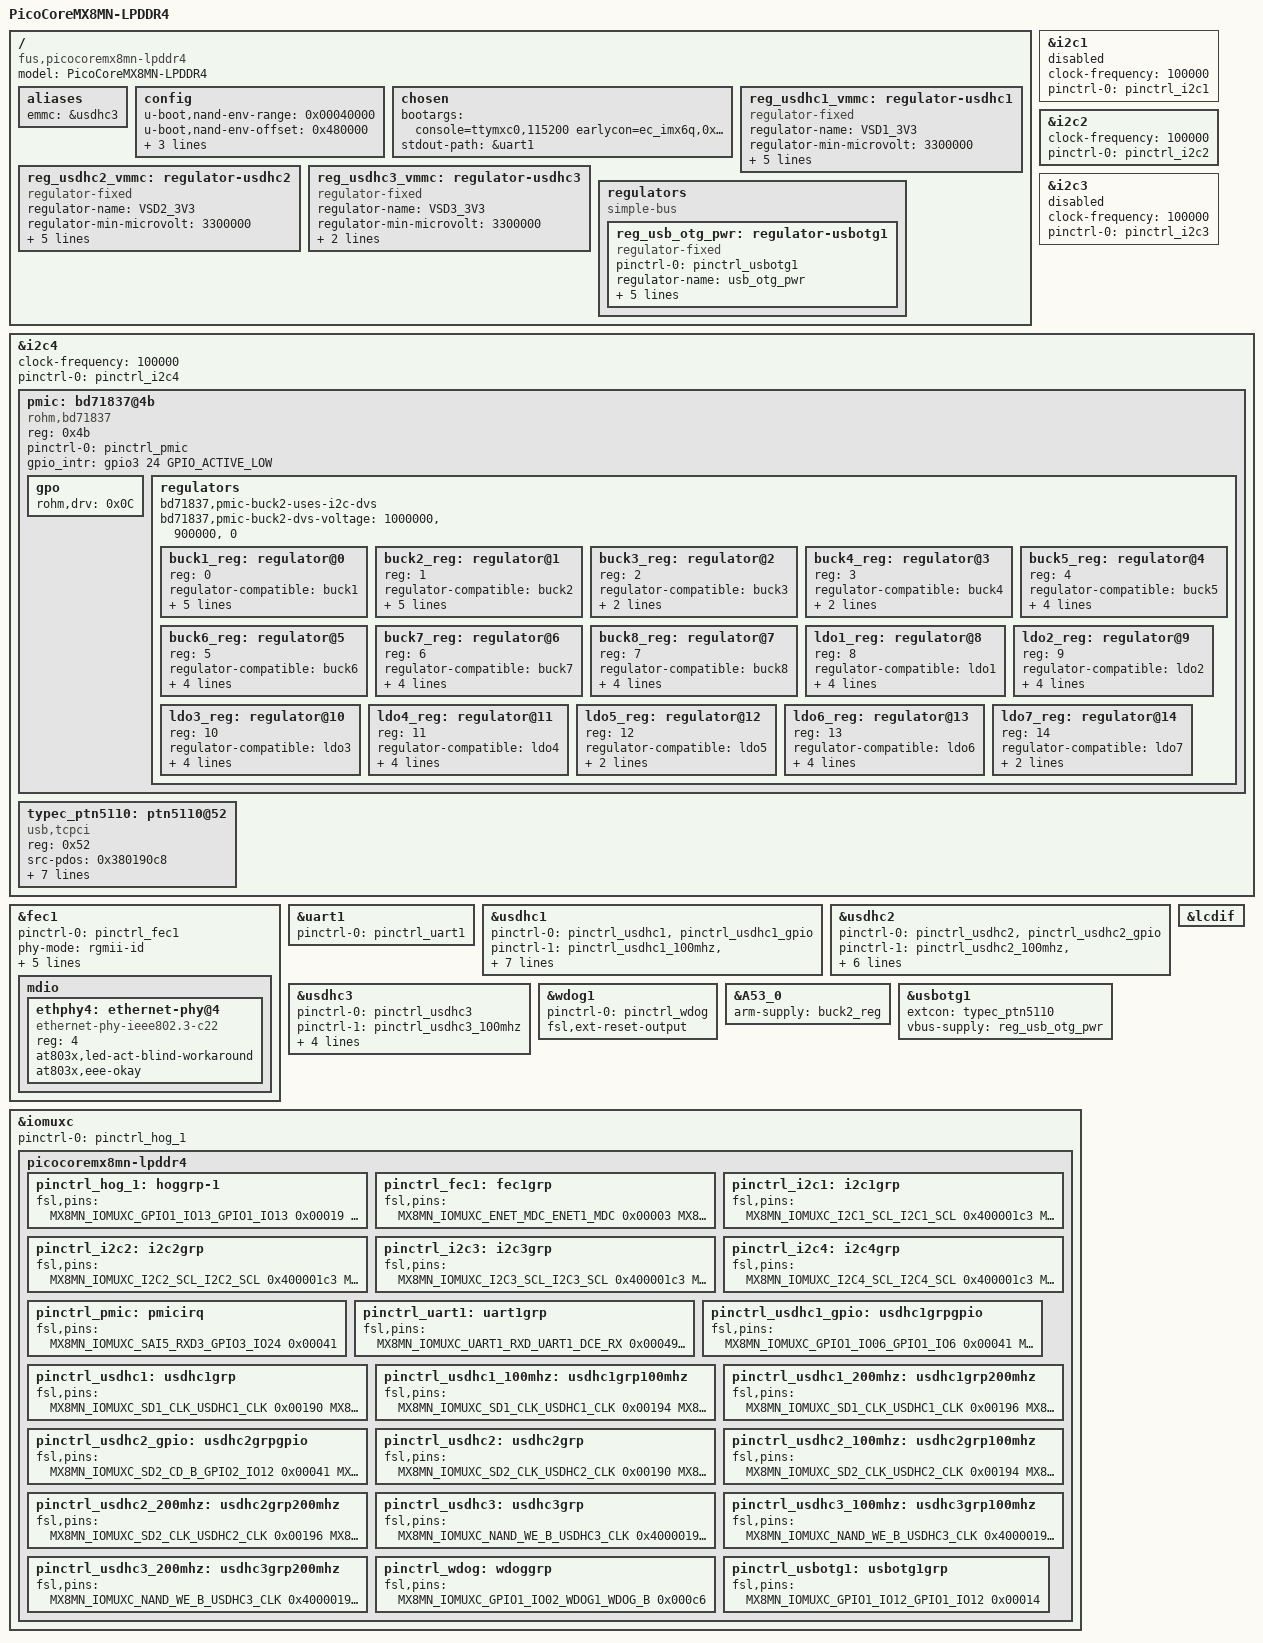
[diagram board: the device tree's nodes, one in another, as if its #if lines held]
/*
* Copyright 2019-2020 F&S Elektronik Systeme GmbH
*
* This program is free software; you can redistribute it and/or
* modify it under the terms of the GNU General Public License
* as published by the Free Software Foundation; either version 2
* of the License, or (at your option) any later version.
*
* This program is distributed in the hope that it will be useful,
* but WITHOUT ANY WARRANTY; without even the implied warranty of
* MERCHANTABILITY or FITNESS FOR A PARTICULAR PURPOSE.  See the
* GNU General Public License for more details.
*
* Remark:
* CONFIG names use "PICOCOREMX8MM" because this is the marking on the PCB.
* This will make it easier to merge the two device trees picocoremx8mm-lpddr4
* and picocoremx8mn-lpddr4 in the future.
*/

/dts-v1/;

/* Set board revision as 3-digit number, e.g. 110 for board rev. 1.10 */
#define CONFIG_PICOCOREMX8MM_BOARD_REVISION	130

 /* Network */
#define CONFIG_PICOCOREMX8MM_ETH

/* USB */
#define CONFIG_PICOCOREMX8MM_USB_OTG1

#define CONFIG_PICOCOREMX8MM_USB_OTG1_TYPEC

/* I2C */
#define CONFIG_PICOCOREMX8MM_I2C_A
#define CONFIG_PICOCOREMX8MM_I2C_B
#define CONFIG_PICOCOREMX8MM_I2C_C
#define CONFIG_PICOCOREMX8MM_I2C_D

/* UART_A - UART1 */
#define CONFIG_PICOCOREMX8MM_UART_A
#define CONFIG_PICOCOREMX8MM_UART_A_RTSCTS


/*
 * SD_A - External SD port with Card Detect (CD) and Write Protect (WP)
 * On PicoCoreMX8MN SKIT: external port is Micro-SD card slot with CD but without WP
 */
#define CONFIG_PICOCOREMX8MM_SD_A
#define CONFIG_PICOCOREMX8MM_SD_A_CD
//#define CONFIG_PICOCOREMX8MM_SD_A_WP

/*
 * SD_B - External SD port with Card Detect (CD) and Write Protect (WP)
 * Not connected on PicoCoreMX8MN SKIT
 */
//#define CONFIG_PICOCOREMX8MM_SD_B
//#define CONFIG_PICOCOREMX8MM_SD_B_CD
//#define CONFIG_PICOCOREMX8MM_SD_B_WP

/* TODO: Power polarity can't be set by DT
*  Default its low for both ports. Use regulator
*  to set pin value to correct state.
*/
/* USB0:
*  Enable regulator to activate
*  power pin for otg host devices.
*/
#define CONFIG_USB_OTG_PWR

#include "imx8mn.dtsi"

/ {
	model = "PicoCoreMX8MN-LPDDR4";
	compatible = "fus,picocoremx8mn-lpddr4", "fsl,imx8mn";

	aliases {
		emmc = &usdhc3;
	};

	config {
		/* Environment in NAND must match UBootEnv MTD partition */
		u-boot,nand-env-range = <0x00040000>;
		u-boot,nand-env-offset = <0x480000>;
		u-boot,nand-env-offset-redundant = <0x4c0000>;

		/* Environment in MMC is in a Boot partition by default */
		u-boot,mmc-env-offset = <0x138000>;
		u-boot,mmc-env-offset-redundant = <0x13c000>;
	};

	chosen {
		bootargs = "console=ttymxc0,115200 earlycon=ec_imx6q,0x30860000,115200";
		stdout-path = &uart1;
	};

#ifdef CONFIG_PICOCOREMX8MM_SD_A
	reg_usdhc1_vmmc: regulator-usdhc1 {
		compatible = "regulator-fixed";
		regulator-name = "VSD1_3V3";
		regulator-min-microvolt = <3300000>;
		regulator-max-microvolt = <3300000>;
		gpio = <&gpio2 10 GPIO_ACTIVE_HIGH>;
		enable-active-high;
		startup-delay-us = <100>;
		off-on-delay-us = <12000>;
	};
#endif

#ifdef CONFIG_PICOCOREMX8MM_SD_B
	reg_usdhc2_vmmc: regulator-usdhc2 {
		compatible = "regulator-fixed";
		regulator-name = "VSD2_3V3";
		regulator-min-microvolt = <3300000>;
		regulator-max-microvolt = <3300000>;
		gpio = <&gpio2 19 GPIO_ACTIVE_HIGH>;
		enable-active-high;
		startup-delay-us = <100>;
		off-on-delay-us = <12000>;
	};
#endif

	reg_usdhc3_vmmc: regulator-usdhc3 {
		compatible = "regulator-fixed";
		regulator-name = "VSD3_3V3";
		regulator-min-microvolt = <3300000>;
		regulator-max-microvolt = <3300000>;
		regulator-always-on;
#if 0
		gpio = <&gpio3 16 GPIO_ACTIVE_HIGH>;
		enable-active-high;
		startup-delay-us = <100>;
		off-on-delay-us = <12000>;
#endif
	};

	regulators {
		compatible = "simple-bus";

#ifdef CONFIG_USB_OTG_PWR
		reg_usb_otg_pwr: regulator-usbotg1 {
			pinctrl-names = "default";
			pinctrl-0 = <&pinctrl_usbotg1>;
			compatible = "regulator-fixed";
			regulator-name = "usb_otg_pwr";
			regulator-min-microvolt = <5000000>;
			regulator-max-microvolt = <5000000>;
			gpio = <&gpio1 12 GPIO_ACTIVE_LOW>;
			startup-delay-us = <100>;
			off-on-delay-us = <12000>;
		};
#endif
	};
};

#ifdef CONFIG_PICOCOREMX8MM_I2C_A
&i2c1 {
	clock-frequency = <100000>;
	pinctrl-names = "default";
	pinctrl-0 = <&pinctrl_i2c1>;
	status = "disabled";
};
#endif

#ifdef CONFIG_PICOCOREMX8MM_I2C_B
&i2c2 {
	clock-frequency = <100000>;
	pinctrl-names = "default";
	pinctrl-0 = <&pinctrl_i2c2>;
	status = "okay";
};
#endif

#ifdef CONFIG_PICOCOREMX8MM_I2C_C
&i2c3 {
	clock-frequency = <100000>;
	pinctrl-names = "default";
	pinctrl-0 = <&pinctrl_i2c3>;
	status = "disabled";
};
#endif

#ifdef CONFIG_PICOCOREMX8MM_I2C_D
&i2c4 {
	clock-frequency = <100000>;
	pinctrl-names = "default";
	pinctrl-0 = <&pinctrl_i2c4>;
	status = "okay";

	pmic: bd71837@4b {
		reg = <0x4b>;
		compatible = "rohm,bd71837";
		/* PMIC BD71837 PMIC_nINT GPIO3_IO24 */
		pinctrl-0 = <&pinctrl_pmic>;
#if CONFIG_PICOCOREMX8MX_BOARD_REVISION < 130
		/* PMIC BD71837 PMIC_nINT SAI5_RXD3: GPIO3_IO24 */
		gpio_intr = <&gpio3 24 GPIO_ACTIVE_LOW>;
#else
		/* PMIC BD71837 PMIC_nINT SAI3_MCLK: GPIO5_IO02 */
		gpio_intr = <&gpio5 2 GPIO_ACTIVE_LOW>;
#endif

		gpo {
			rohm,drv = <0x0C>;	/* 0b0000_1100 all gpos with cmos output mode */
		};

		regulators {
			#address-cells = <1>;
			#size-cells = <0>;

			bd71837,pmic-buck2-uses-i2c-dvs;
			bd71837,pmic-buck2-dvs-voltage = <1000000>, <900000>, <0>; /* VDD_ARM: Run-Idle */

			buck1_reg: regulator@0 {
				reg = <0>;
				regulator-compatible = "buck1";
				regulator-min-microvolt = <700000>;
				regulator-max-microvolt = <1300000>;
				regulator-boot-on;
				regulator-always-on;
				regulator-ramp-delay = <1250>;
			};

			buck2_reg: regulator@1 {
				reg = <1>;
				regulator-compatible = "buck2";
				regulator-min-microvolt = <700000>;
				regulator-max-microvolt = <1300000>;
				regulator-boot-on;
				regulator-always-on;
				regulator-ramp-delay = <1250>;
			};

			buck3_reg: regulator@2 {
				reg = <2>;
				regulator-compatible = "buck3";
				regulator-min-microvolt = <700000>;
				regulator-max-microvolt = <1300000>;
			};

			buck4_reg: regulator@3 {
				reg = <3>;
				regulator-compatible = "buck4";
				regulator-min-microvolt = <700000>;
				regulator-max-microvolt = <1300000>;
			};

			buck5_reg: regulator@4 {
				reg = <4>;
				regulator-compatible = "buck5";
				regulator-min-microvolt = <700000>;
				regulator-max-microvolt = <1350000>;
				regulator-boot-on;
				regulator-always-on;
			};

			buck6_reg: regulator@5 {
				reg = <5>;
				regulator-compatible = "buck6";
				regulator-min-microvolt = <3000000>;
				regulator-max-microvolt = <3300000>;
				regulator-boot-on;
				regulator-always-on;
			};

			buck7_reg: regulator@6 {
				reg = <6>;
				regulator-compatible = "buck7";
				regulator-min-microvolt = <1605000>;
				regulator-max-microvolt = <1995000>;
				regulator-boot-on;
				regulator-always-on;
			};

			buck8_reg: regulator@7 {
				reg = <7>;
				regulator-compatible = "buck8";
				regulator-min-microvolt = <800000>;
				regulator-max-microvolt = <1400000>;
				regulator-boot-on;
				regulator-always-on;
			};

			ldo1_reg: regulator@8 {
				reg = <8>;
				regulator-compatible = "ldo1";
				regulator-min-microvolt = <1600000>;
				regulator-max-microvolt = <1900000>;
				regulator-boot-on;
				regulator-always-on;
			};

			ldo2_reg: regulator@9 {
				reg = <9>;
				regulator-compatible = "ldo2";
				regulator-min-microvolt = <800000>;
				regulator-max-microvolt = <900000>;
				regulator-boot-on;
				regulator-always-on;
			};

			ldo3_reg: regulator@10 {
				reg = <10>;
				regulator-compatible = "ldo3";
				regulator-min-microvolt = <1800000>;
				regulator-max-microvolt = <3300000>;
				regulator-boot-on;
				regulator-always-on;
			};

			ldo4_reg: regulator@11 {
				reg = <11>;
				regulator-compatible = "ldo4";
				regulator-min-microvolt = <900000>;
				regulator-max-microvolt = <1800000>;
				regulator-boot-on;
				regulator-always-on;
			};

			ldo5_reg: regulator@12 {
				reg = <12>;
				regulator-compatible = "ldo5";
				regulator-min-microvolt = <1800000>;
				regulator-max-microvolt = <3300000>;
			};

			ldo6_reg: regulator@13 {
				reg = <13>;
				regulator-compatible = "ldo6";
				regulator-min-microvolt = <900000>;
				regulator-max-microvolt = <1800000>;
				regulator-boot-on;
				regulator-always-on;
			};

			ldo7_reg: regulator@14 {
				reg = <14>;
				regulator-compatible = "ldo7";
				regulator-min-microvolt = <1800000>;
				regulator-max-microvolt = <3300000>;
			};
		};
	};
#ifdef CONFIG_PICOCOREMX8MM_USB_OTG1_TYPEC
	/* USB Type-C Chip */
	typec_ptn5110: ptn5110@52 {
		compatible = "usb,tcpci";
		reg = <0x52>;
		src-pdos = <0x380190c8>;
		snk-pdos = <0x380190c8 0x3802d0c8>;
		max-snk-mv = <9000>;
		max-snk-ma = <2000>;
		op-snk-mw = <9000>;
		max-snk-mw = <18000>;
		port-type = "drp";
		default-role = "sink";
	};
#endif
};
#endif

#ifdef CONFIG_PICOCOREMX8MM_ETH
&fec1 {
	pinctrl-names = "default";
	pinctrl-0 = <&pinctrl_fec1>;
	phy-mode = "rgmii-id";
	phy-reset-gpios = <&gpio1 5 GPIO_ACTIVE_LOW>;
	phy-reset-duration = <11>;
	phy-reset-post-delay=<1>;
	phy-handle = <&ethphy4>;
	fsl,magic-packet;
	status = "okay";

	mdio {
		#address-cells = <1>;
		#size-cells = <0>;

		ethphy4: ethernet-phy@4 {
			compatible = "ethernet-phy-ieee802.3-c22";
			reg = <4>;
			at803x,led-act-blind-workaround;
			at803x,eee-okay;
		};
	};
};
#endif

#ifdef CONFIG_PICOCOREMX8MM_UART_A
&uart1 { /* console */
	pinctrl-names = "default";
	pinctrl-0 = <&pinctrl_uart1>;
	status = "okay";
};
#endif

#ifdef CONFIG_PICOCOREMX8MM_SD_A
&usdhc1 {
	pinctrl-names = "default", "state_100mhz", "state_200mhz";
	pinctrl-0 = <&pinctrl_usdhc1>, <&pinctrl_usdhc1_gpio>;
	pinctrl-1 = <&pinctrl_usdhc1_100mhz>, <&pinctrl_usdhc1_gpio>;
	pinctrl-2 = <&pinctrl_usdhc1_200mhz>, <&pinctrl_usdhc1_gpio>;
	bus-width = <4>;
#ifdef CONFIG_PICOCOREMX8MM_SD_A_CD
	cd-gpios = <&gpio1 6 GPIO_ACTIVE_LOW>;
#endif
#ifdef CONFIG_PICOCOREMX8MM_SD_A_WP
	wp-gpios = <&gpio1 7 GPIO_ACTIVE_HIGH>;
#endif
	/* reset pin will used as vmmc supply */
	vmmc-supply = <&reg_usdhc1_vmmc>;
	status = "okay";
};
#endif

#ifdef CONFIG_PICOCOREMX8MM_SD_B
&usdhc2 {
	pinctrl-names = "default", "state_100mhz", "state_200mhz";
	pinctrl-0 = <&pinctrl_usdhc2>, <&pinctrl_usdhc2_gpio>;
	pinctrl-1 = <&pinctrl_usdhc2_100mhz>, <&pinctrl_usdhc2_gpio>;
	pinctrl-2 = <&pinctrl_usdhc2_200mhz>, <&pinctrl_usdhc2_gpio>;
	bus-width = <4>;
	cd-gpios = <&gpio2 12 GPIO_ACTIVE_LOW>;
	vmmc-supply = <&reg_usdhc2_vmmc>;
	status = "okay";
};
#endif

&usdhc3 {
	pinctrl-names = "default", "state_100mhz", "state_200mhz";
	pinctrl-0 = <&pinctrl_usdhc3>;
	pinctrl-1 = <&pinctrl_usdhc3_100mhz>;
	pinctrl-2 = <&pinctrl_usdhc3_200mhz>;
	bus-width = <8>;
	non-removable;
	vmmc-supply = <&reg_usdhc3_vmmc>;
	status = "okay";
};

&wdog1 {
	pinctrl-names = "default";
	pinctrl-0 = <&pinctrl_wdog>;
	fsl,ext-reset-output;
	status = "okay";
};

&A53_0 {
	arm-supply = <&buck2_reg>;
};

#ifdef CONFIG_PICOCOREMX8MM_USB_OTG1
&usbotg1 {
#ifdef CONFIG_PICOCOREMX8MM_USB_OTG1_TYPEC
	extcon = <&typec_ptn5110>;
#else
	dr_mode = "otg";
#endif
	#ifdef CONFIG_USB_OTG_PWR
	vbus-supply = <&reg_usb_otg_pwr>;
	#else
	pinctrl-names = "default";
	pinctrl-0 = <&pinctrl_usbotg1>;
	#endif
	status = "okay";
};
#endif

&lcdif {
	status = "okay";
};

&iomuxc {
	pinctrl-names = "default";
	pinctrl-0 = <&pinctrl_hog_1>;

	picocoremx8mn-lpddr4 {
		pinctrl_hog_1: hoggrp-1 {
			fsl,pins = <
				/* LVDS_RST */
				MX8MN_IOMUXC_GPIO1_IO13_GPIO1_IO13	0x00019
				/* CLKO2 -> EXTCLK */
				MX8MN_IOMUXC_GPIO1_IO15_CCMSRCGPCMIX_CLKO2	0x00059
			>;
		};

#ifdef CONFIG_PICOCOREMX8MM_ETH
		pinctrl_fec1: fec1grp {
			fsl,pins = <
				MX8MN_IOMUXC_ENET_MDC_ENET1_MDC		0x00003
				MX8MN_IOMUXC_ENET_MDIO_ENET1_MDIO	0x00003
				MX8MN_IOMUXC_ENET_TD3_ENET1_RGMII_TD3	0x0001f
				MX8MN_IOMUXC_ENET_TD2_ENET1_RGMII_TD2	0x0001f
				MX8MN_IOMUXC_ENET_TD1_ENET1_RGMII_TD1	0x0001f
				MX8MN_IOMUXC_ENET_TD0_ENET1_RGMII_TD0	0x0001f
				MX8MN_IOMUXC_ENET_RD3_ENET1_RGMII_RD3	0x00091
				MX8MN_IOMUXC_ENET_RD2_ENET1_RGMII_RD2	0x00091
				MX8MN_IOMUXC_ENET_RD1_ENET1_RGMII_RD1	0x00091
				MX8MN_IOMUXC_ENET_RD0_ENET1_RGMII_RD0	0x00091
				MX8MN_IOMUXC_ENET_TXC_ENET1_RGMII_TXC	0x0001f
				MX8MN_IOMUXC_ENET_RXC_ENET1_RGMII_RXC	0x00091
				MX8MN_IOMUXC_ENET_RX_CTL_ENET1_RGMII_RX_CTL	0x00091
				MX8MN_IOMUXC_ENET_TX_CTL_ENET1_RGMII_TX_CTL	0x0001f
				/* ETH_A_PHY_INTn */
				MX8MN_IOMUXC_GPIO1_IO04_GPIO1_IO4	0x00019
				/* ETH_A_PHY_RST  */
				MX8MN_IOMUXC_GPIO1_IO05_GPIO1_IO5	0x00019
			>;
		};
#endif

#ifdef CONFIG_PICOCOREMX8MM_I2C_A
		pinctrl_i2c1: i2c1grp {
			fsl,pins = <
				MX8MN_IOMUXC_I2C1_SCL_I2C1_SCL		0x400001c3
				MX8MN_IOMUXC_I2C1_SDA_I2C1_SDA		0x400001c3
			>;
		};
#endif

#ifdef CONFIG_PICOCOREMX8MM_I2C_B
		pinctrl_i2c2: i2c2grp {
			fsl,pins = <
				MX8MN_IOMUXC_I2C2_SCL_I2C2_SCL		0x400001c3
				MX8MN_IOMUXC_I2C2_SDA_I2C2_SDA		0x400001c3
			>;
		};
#endif

#ifdef CONFIG_PICOCOREMX8MM_I2C_C
		pinctrl_i2c3: i2c3grp {
			fsl,pins = <
				MX8MN_IOMUXC_I2C3_SCL_I2C3_SCL		0x400001c3
				MX8MN_IOMUXC_I2C3_SDA_I2C3_SDA		0x400001c3
			>;
		};
#endif

#ifdef CONFIG_PICOCOREMX8MM_I2C_D
		pinctrl_i2c4: i2c4grp {
			fsl,pins = <
				MX8MN_IOMUXC_I2C4_SCL_I2C4_SCL		0x400001c3
				MX8MN_IOMUXC_I2C4_SDA_I2C4_SDA		0x400001c3
			>;
		};

		pinctrl_pmic: pmicirq {
			fsl,pins = <
#if CONFIG_PICOCOREMX8MX_BOARD_REVISION < 130
				MX8MN_IOMUXC_SAI5_RXD3_GPIO3_IO24	0x00041
#else
				MX8MN_IOMUXC_SAI3_MCLK_GPIO5_IO02	0x00041
#endif
			>;
		};
#endif

#ifdef CONFIG_PICOCOREMX8MM_UART_A
		pinctrl_uart1: uart1grp {
			fsl,pins = <
				MX8MN_IOMUXC_UART1_RXD_UART1_DCE_RX	0x00049
				MX8MN_IOMUXC_UART1_TXD_UART1_DCE_TX	0x00049
			>;
		};
#endif

#ifdef CONFIG_PICOCOREMX8MM_SD_A
		pinctrl_usdhc1_gpio: usdhc1grpgpio {
			fsl,pins = <
#ifdef CONFIG_PICOCOREMX8MM_SD_A_CD
				MX8MN_IOMUXC_GPIO1_IO06_GPIO1_IO6	0x00041
#endif
#ifdef CONFIG_PICOCOREMX8MM_SD_A_WP
				MX8MN_IOMUXC_GPIO1_IO07_GPIO1_IO7	0x00041
#endif
				MX8MN_IOMUXC_SD1_RESET_B_GPIO2_IO10	0x00041
			>;
		};

		pinctrl_usdhc1: usdhc1grp {
			fsl,pins = <
				MX8MN_IOMUXC_SD1_CLK_USDHC1_CLK		0x00190
				MX8MN_IOMUXC_SD1_CMD_USDHC1_CMD		0x001d0
				MX8MN_IOMUXC_SD1_DATA0_USDHC1_DATA0	0x001d0
				MX8MN_IOMUXC_SD1_DATA1_USDHC1_DATA1	0x001d0
				MX8MN_IOMUXC_SD1_DATA2_USDHC1_DATA2	0x001d0
				MX8MN_IOMUXC_SD1_DATA3_USDHC1_DATA3	0x001d0
				MX8MN_IOMUXC_GPIO1_IO03_USDHC1_VSELECT	0x001d0
			>;
		};

		pinctrl_usdhc1_100mhz: usdhc1grp100mhz {
			fsl,pins = <
				MX8MN_IOMUXC_SD1_CLK_USDHC1_CLK		0x00194
				MX8MN_IOMUXC_SD1_CMD_USDHC1_CMD		0x001d4
				MX8MN_IOMUXC_SD1_DATA0_USDHC1_DATA0	0x001d4
				MX8MN_IOMUXC_SD1_DATA1_USDHC1_DATA1	0x001d4
				MX8MN_IOMUXC_SD1_DATA2_USDHC1_DATA2	0x001d4
				MX8MN_IOMUXC_SD1_DATA3_USDHC1_DATA3	0x001d4
				MX8MN_IOMUXC_GPIO1_IO03_USDHC1_VSELECT	0x001d0
			>;
		};

		pinctrl_usdhc1_200mhz: usdhc1grp200mhz {
			fsl,pins = <
				MX8MN_IOMUXC_SD1_CLK_USDHC1_CLK		0x00196
				MX8MN_IOMUXC_SD1_CMD_USDHC1_CMD		0x001d6
				MX8MN_IOMUXC_SD1_DATA0_USDHC1_DATA0	0x001d6
				MX8MN_IOMUXC_SD1_DATA1_USDHC1_DATA1	0x001d6
				MX8MN_IOMUXC_SD1_DATA2_USDHC1_DATA2	0x001d6
				MX8MN_IOMUXC_SD1_DATA3_USDHC1_DATA3	0x001d6
				MX8MN_IOMUXC_GPIO1_IO03_USDHC1_VSELECT	0x001d0
			>;
		};
#endif

#ifdef CONFIG_PICOCOREMX8MM_SD_B
		pinctrl_usdhc2_gpio: usdhc2grpgpio {
			fsl,pins = <
				MX8MN_IOMUXC_SD2_CD_B_GPIO2_IO12	0x00041
				MX8MN_IOMUXC_SD2_RESET_B_GPIO2_IO19	0x00041
			>;
		};

		pinctrl_usdhc2: usdhc2grp {
			fsl,pins = <
				MX8MN_IOMUXC_SD2_CLK_USDHC2_CLK		0x00190
				MX8MN_IOMUXC_SD2_CMD_USDHC2_CMD		0x001d0
				MX8MN_IOMUXC_SD2_DATA0_USDHC2_DATA0	0x001d0
				MX8MN_IOMUXC_SD2_DATA1_USDHC2_DATA1	0x001d0
				MX8MN_IOMUXC_SD2_DATA2_USDHC2_DATA2	0x001d0
				MX8MN_IOMUXC_SD2_DATA3_USDHC2_DATA3	0x001d0
				MX8MN_IOMUXC_GPIO1_IO04_USDHC2_VSELECT	0x001d0
			>;
		};

		pinctrl_usdhc2_100mhz: usdhc2grp100mhz {
			fsl,pins = <
				MX8MN_IOMUXC_SD2_CLK_USDHC2_CLK		0x00194
				MX8MN_IOMUXC_SD2_CMD_USDHC2_CMD		0x001d4
				MX8MN_IOMUXC_SD2_DATA0_USDHC2_DATA0	0x001d4
				MX8MN_IOMUXC_SD2_DATA1_USDHC2_DATA1	0x001d4
				MX8MN_IOMUXC_SD2_DATA2_USDHC2_DATA2	0x001d4
				MX8MN_IOMUXC_SD2_DATA3_USDHC2_DATA3	0x001d4
				MX8MN_IOMUXC_GPIO1_IO04_USDHC2_VSELECT	0x001d0
			>;
		};

		pinctrl_usdhc2_200mhz: usdhc2grp200mhz {
			fsl,pins = <
				MX8MN_IOMUXC_SD2_CLK_USDHC2_CLK		0x00196
				MX8MN_IOMUXC_SD2_CMD_USDHC2_CMD		0x001d6
				MX8MN_IOMUXC_SD2_DATA0_USDHC2_DATA0	0x001d6
				MX8MN_IOMUXC_SD2_DATA1_USDHC2_DATA1	0x001d6
				MX8MN_IOMUXC_SD2_DATA2_USDHC2_DATA2	0x001d6
				MX8MN_IOMUXC_SD2_DATA3_USDHC2_DATA3	0x001d6
				MX8MN_IOMUXC_GPIO1_IO04_USDHC2_VSELECT	0x001d0
			>;
		};
#endif

		pinctrl_usdhc3: usdhc3grp {
			fsl,pins = <
				MX8MN_IOMUXC_NAND_WE_B_USDHC3_CLK	0x40000190
				MX8MN_IOMUXC_NAND_WP_B_USDHC3_CMD	0x001d0
				MX8MN_IOMUXC_NAND_DATA04_USDHC3_DATA0	0x001d0
				MX8MN_IOMUXC_NAND_DATA05_USDHC3_DATA1	0x001d0
				MX8MN_IOMUXC_NAND_DATA06_USDHC3_DATA2	0x001d0
				MX8MN_IOMUXC_NAND_DATA07_USDHC3_DATA3	0x001d0
				MX8MN_IOMUXC_NAND_RE_B_USDHC3_DATA4	0x001d0
				MX8MN_IOMUXC_NAND_CE2_B_USDHC3_DATA5	0x001d0
				MX8MN_IOMUXC_NAND_CE3_B_USDHC3_DATA6	0x001d0
				MX8MN_IOMUXC_NAND_CLE_USDHC3_DATA7	0x001d0
				MX8MN_IOMUXC_NAND_CE1_B_USDHC3_STROBE 	0x00190
				MX8MN_IOMUXC_NAND_READY_B_USDHC3_RESET_B	0x00190
			>;
		};

		pinctrl_usdhc3_100mhz: usdhc3grp100mhz {
			fsl,pins = <
				MX8MN_IOMUXC_NAND_WE_B_USDHC3_CLK	0x40000194
				MX8MN_IOMUXC_NAND_WP_B_USDHC3_CMD	0x001d4
				MX8MN_IOMUXC_NAND_DATA04_USDHC3_DATA0	0x001d4
				MX8MN_IOMUXC_NAND_DATA05_USDHC3_DATA1	0x001d4
				MX8MN_IOMUXC_NAND_DATA06_USDHC3_DATA2	0x001d4
				MX8MN_IOMUXC_NAND_DATA07_USDHC3_DATA3	0x001d4
				MX8MN_IOMUXC_NAND_RE_B_USDHC3_DATA4	0x001d4
				MX8MN_IOMUXC_NAND_CE2_B_USDHC3_DATA5	0x001d4
				MX8MN_IOMUXC_NAND_CE3_B_USDHC3_DATA6	0x001d4
				MX8MN_IOMUXC_NAND_CLE_USDHC3_DATA7	0x001d4
				MX8MN_IOMUXC_NAND_CE1_B_USDHC3_STROBE 	0x00194
				MX8MN_IOMUXC_NAND_READY_B_USDHC3_RESET_B	0x001d4
			>;
		};

		pinctrl_usdhc3_200mhz: usdhc3grp200mhz {
			fsl,pins = <
				MX8MN_IOMUXC_NAND_WE_B_USDHC3_CLK	0x40000196
				MX8MN_IOMUXC_NAND_WP_B_USDHC3_CMD	0x001d6
				MX8MN_IOMUXC_NAND_DATA04_USDHC3_DATA0	0x001d6
				MX8MN_IOMUXC_NAND_DATA05_USDHC3_DATA1	0x001d6
				MX8MN_IOMUXC_NAND_DATA06_USDHC3_DATA2	0x001d6
				MX8MN_IOMUXC_NAND_DATA07_USDHC3_DATA3	0x001d6
				MX8MN_IOMUXC_NAND_RE_B_USDHC3_DATA4	0x001d6
				MX8MN_IOMUXC_NAND_CE2_B_USDHC3_DATA5	0x001d6
				MX8MN_IOMUXC_NAND_CE3_B_USDHC3_DATA6	0x001d6
				MX8MN_IOMUXC_NAND_CLE_USDHC3_DATA7	0x001d6
				MX8MN_IOMUXC_NAND_CE1_B_USDHC3_STROBE 	0x00196
				MX8MN_IOMUXC_NAND_READY_B_USDHC3_RESET_B	0x001d6
			>;
		};

		pinctrl_wdog: wdoggrp {
			fsl,pins = <
				MX8MN_IOMUXC_GPIO1_IO02_WDOG1_WDOG_B	0x000c6
			>;
		};

		pinctrl_usbotg1: usbotg1grp {
			fsl,pins = <
				#ifdef CONFIG_USB_OTG_PWR
				MX8MN_IOMUXC_GPIO1_IO12_GPIO1_IO12	0x00014
				#else
				MX8MN_IOMUXC_GPIO1_IO12_USB1_OTG_PWR	0x00014
				#endif
			>;
		};
	};
};
